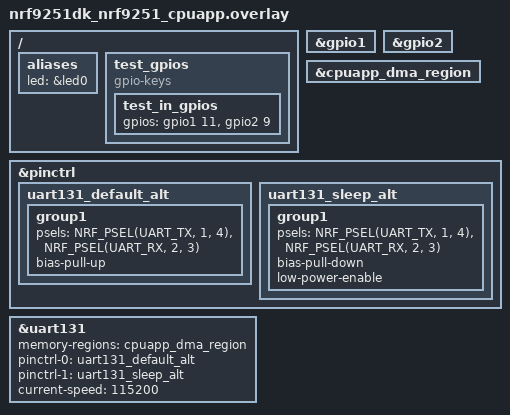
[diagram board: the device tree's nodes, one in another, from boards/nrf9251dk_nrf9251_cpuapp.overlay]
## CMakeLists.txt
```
#
# Copyright (c) 2026 Nordic Semiconductor ASA
#
# SPDX-License-Identifier: LicenseRef-Nordic-5-Clause
#

cmake_minimum_required(VERSION 3.20.0)

find_package(Zephyr REQUIRED HINTS $ENV{ZEPHYR_BASE})

project(uart_pins_pm)

target_sources(app PRIVATE src/main.c)
```

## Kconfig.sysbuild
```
#
# Copyright (c) 2026 Nordic Semiconductor ASA
#
# SPDX-License-Identifier: LicenseRef-Nordic-5-Clause
#

config REMOTE_BOARD
	string
	default "$(BOARD)/nrf54h20/cpurad" if SOC_NRF54H20_CPUAPP

source "share/sysbuild/Kconfig"
```

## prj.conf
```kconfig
CONFIG_SERIAL=y
CONFIG_UART_ASYNC_API=y

CONFIG_PM=y
CONFIG_PM_DEVICE=y
CONFIG_PM_DEVICE_RUNTIME=y
CONFIG_POWEROFF=y

CONFIG_BOOT_BANNER=n
CONFIG_NCS_BOOT_BANNER=n
CONFIG_ASSERT=y

# Enable for debugging purposes only
CONFIG_PRINTK=n
CONFIG_LOG=n
CONFIG_CONSOLE=n
CONFIG_UART_CONSOLE=n
```

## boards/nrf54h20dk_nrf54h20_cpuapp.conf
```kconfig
#
# Copyright (c) 2026 Nordic Semiconductor ASA
#
# SPDX-License-Identifier: LicenseRef-Nordic-5-Clause
#

CONFIG_SOC_NRF54H20_CPURAD_ENABLE=y
```

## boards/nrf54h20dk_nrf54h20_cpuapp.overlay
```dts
/*
 * Copyright (c) 2026 Nordic Semiconductor ASA
 *
 * SPDX-License-Identifier: LicenseRef-Nordic-5-Clause
 */

/*
 * Required loopbacks
 * P0.00 - P0.01
 * P0.02 - P0.04
 * P0.03 - P0.05
 * P0.06 - P0.07
 */

/ {
	aliases {
		led = &led0;
		/delete-property/ led1;
	};

	test_gpios {
		compatible = "gpio-keys";

		test_in_gpios: test_in_gpios {
			gpios = <&gpio0 1 GPIO_ACTIVE_HIGH>, <&gpio0 4 GPIO_ACTIVE_HIGH>,
				<&gpio0 5 GPIO_ACTIVE_HIGH>, <&gpio0 7 GPIO_ACTIVE_HIGH>;
		};
	};
};

/delete-node/ &led1;

&gpio0 {
	status = "okay";
};

&cpuapp_dma_region {
	status = "okay";
};

&pinctrl {
	uart132_default_alt: uart132_default_alt {
		group1 {
			psels = <NRF_PSEL(UART_TX, 0, 0)>,
				<NRF_PSEL(UART_RX, 0, 2)>,
				<NRF_PSEL(UART_RTS, 0, 3)>,
				<NRF_PSEL(UART_CTS, 0, 6)>;
			bias-pull-up;
		};
	};

	uart132_sleep_alt: uart132_sleep_alt {
		group1 {
			psels = <NRF_PSEL(UART_TX, 0, 0)>,
				<NRF_PSEL(UART_RX, 0, 2)>,
				<NRF_PSEL(UART_RTS, 0, 3)>,
				<NRF_PSEL(UART_CTS, 0, 6)>;
			bias-pull-down;
			low-power-enable;
		};
	};
};

dut: &uart132 {
	status = "okay";
	memory-regions = <&cpuapp_dma_region>;
	pinctrl-0 = <&uart132_default_alt>;
	pinctrl-1 = <&uart132_sleep_alt>;
	pinctrl-names = "default", "sleep";
	current-speed = <115200>;
	hw-flow-control;
	/delete-property/ zephyr,pm-device-runtime-auto;
};
```

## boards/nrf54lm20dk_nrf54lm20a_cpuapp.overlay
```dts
/*
 * Copyright (c) 2026 Nordic Semiconductor ASA
 *
 * SPDX-License-Identifier: LicenseRef-Nordic-5-Clause
 */

/*
 * Required loopbacks
 * P1.03 - P1.04
 * P1.13 - P1.14
 * P1.23 - P1.24
 * P1.30 - P1.31
 */

/ {
	aliases {
		led = &led0;
		/delete-property/ led1;
	};
};

/delete-node/ &led1;

/ {
	aliases {
		led = &led0;
		/delete-property/ led1;
	};

	test_gpios {
		compatible = "gpio-keys";

		test_in_gpios: test_in_gpios {
			gpios = <&gpio1 4 GPIO_ACTIVE_HIGH>, <&gpio1 14 GPIO_ACTIVE_HIGH>,
				<&gpio1 24 GPIO_ACTIVE_HIGH>, <&gpio1 31 GPIO_ACTIVE_HIGH>;
		};
	};
};

&gpio1 {
	status = "okay";
};

&pinctrl {
	uart21_default_alt: uart21_default_alt {
		group1 {
			psels = <NRF_PSEL(UART_TX, 1, 3)>,
				<NRF_PSEL(UART_RX, 1, 13)>,
				<NRF_PSEL(UART_RTS, 1, 23)>,
				<NRF_PSEL(UART_CTS, 1, 30)>;
			bias-pull-up;
		};
	};

	uart21_sleep_alt: uart21_sleep_alt {
		group1 {
			psels = <NRF_PSEL(UART_TX, 1, 3)>,
				<NRF_PSEL(UART_RX, 1, 13)>,
				<NRF_PSEL(UART_RTS, 1, 23)>,
				<NRF_PSEL(UART_CTS, 1, 30)>;
			bias-pull-down;
			low-power-enable;
		};
	};
};

dut: &uart21 {
	status = "okay";
	current-speed = <115200>;
	pinctrl-0 = <&uart21_default_alt>;
	pinctrl-1 = <&uart21_sleep_alt>;
	pinctrl-names = "default", "sleep";
	/delete-property/ zephyr,pm-device-runtime-auto;
};
```

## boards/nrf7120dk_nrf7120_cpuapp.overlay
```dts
/*
 * Copyright (c) 2026 Nordic Semiconductor ASA
 *
 * SPDX-License-Identifier: LicenseRef-Nordic-5-Clause
 */

/*
 * Required loopbacks
 * P1.07 - P1.12
 * P1.13 - P1.15
 * P1.14 - P1.05
 * P1.04 - P1.06
 */

/ {
	aliases {
		led = &led0;
		/delete-property/ led1;
	};
};

/delete-node/ &led1;

/ {
	aliases {
		led = &led0;
		/delete-property/ led1;
	};

	test_gpios {
		compatible = "gpio-keys";

		test_in_gpios: test_in_gpios {
			gpios = <&gpio1 7 GPIO_ACTIVE_HIGH>, <&gpio1 13 GPIO_ACTIVE_HIGH>,
				<&gpio1 14 GPIO_ACTIVE_HIGH>, <&gpio1 4 GPIO_ACTIVE_HIGH>;
		};
	};
};

&gpio1 {
	status = "okay";
};

&pinctrl {
	uart21_default_alt: uart21_default_alt {
		group1 {
			psels = <NRF_PSEL(UART_TX, 1, 12)>,
				<NRF_PSEL(UART_RX, 1, 15)>,
				<NRF_PSEL(UART_RTS, 1, 5)>,
				<NRF_PSEL(UART_CTS, 1, 6)>;
			bias-pull-up;
		};
	};

	uart21_sleep_alt: uart21_sleep_alt {
		group1 {
			psels = <NRF_PSEL(UART_TX, 1, 12)>,
				<NRF_PSEL(UART_RX, 1, 15)>,
				<NRF_PSEL(UART_RTS, 1, 5)>,
				<NRF_PSEL(UART_CTS, 1, 6)>;
			bias-pull-down;
			low-power-enable;
		};
	};
};

dut: &uart21 {
	status = "okay";
	current-speed = <115200>;
	pinctrl-0 = <&uart21_default_alt>;
	pinctrl-1 = <&uart21_sleep_alt>;
	pinctrl-names = "default", "sleep";
	/delete-property/ zephyr,pm-device-runtime-auto;
};

&gpio4 {
	status = "disabled";
};
```

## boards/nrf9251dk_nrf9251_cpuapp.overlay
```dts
/*
 * Copyright (c) 2026 Nordic Semiconductor ASA
 *
 * SPDX-License-Identifier: LicenseRef-Nordic-5-Clause
 */

/*
 * Required loopbacks
 * P1.04 - P1.11
 * P2.03 - P2.09
 */

/ {
	aliases {
		led = &led0;
	};

	test_gpios {
		compatible = "gpio-keys";

		test_in_gpios: test_in_gpios {
			gpios = <&gpio1 11 GPIO_ACTIVE_HIGH>, <&gpio2 9 GPIO_ACTIVE_HIGH>;
		};
	};
};

&gpio1 {
	status = "okay";
};

&gpio2 {
	status = "okay";
};

&cpuapp_dma_region {
	status = "okay";
};

&pinctrl {
	uart131_default_alt: uart131_default_alt {
		group1 {
			psels = <NRF_PSEL(UART_TX, 1, 4)>,
				<NRF_PSEL(UART_RX, 2, 3)>;
			bias-pull-up;
		};
	};

	uart131_sleep_alt: uart131_sleep_alt {
		group1 {
			psels = <NRF_PSEL(UART_TX, 1, 4)>,
				<NRF_PSEL(UART_RX, 2, 3)>;
			bias-pull-down;
			low-power-enable;
		};
	};
};

dut: &uart131 {
	status = "okay";
	memory-regions = <&cpuapp_dma_region>;
	pinctrl-0 = <&uart131_default_alt>;
	pinctrl-1 = <&uart131_sleep_alt>;
	pinctrl-names = "default", "sleep";
	current-speed = <115200>;
	/delete-property/ hw-flow-control;
	/delete-property/ zephyr,pm-device-runtime-auto;
};
```

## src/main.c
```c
/*
 * Copyright (c) 2026 Nordic Semiconductor ASA
 *
 * SPDX-License-Identifier: LicenseRef-Nordic-5-Clause
 */

#include <zephyr/drivers/uart.h>
#include <zephyr/pm/device_runtime.h>
#include <zephyr/pm/device.h>
#include <zephyr/kernel.h>
#include <zephyr/drivers/gpio.h>

static const struct device *const console_dev = DEVICE_DT_GET(DT_CHOSEN(zephyr_console));

#if DT_NODE_EXISTS(DT_NODELABEL(dut))
#define UART_NODE DT_NODELABEL(dut)
#else
#error Improper device tree configuration, UARTE test node not available
#endif

#define SLEEP_TIME_MS		    1000
#define UART_ACTION_BASE_TIMEOUT_US 1000
#define TEST_BUFFER_LEN		    10

static uint8_t test_buffer[TEST_BUFFER_LEN];
const uint8_t test_pattern[TEST_BUFFER_LEN] = {0x11, 0x12, 0x13, 0x14, 0x15,
					       0x16, 0x17, 0x18, 0x19, 0x20};

static const struct device *const uart_dev = DEVICE_DT_GET(UART_NODE);
static const struct gpio_dt_spec led = GPIO_DT_SPEC_GET(DT_ALIAS(led), gpios);

const struct gpio_dt_spec test_pins[] = {DT_FOREACH_PROP_ELEM_SEP(
	DT_NODELABEL(test_in_gpios), gpios, GPIO_DT_SPEC_GET_BY_IDX, (,))};

static void async_uart_callback(const struct device *dev, struct uart_event *evt, void *user_data)
{
	switch (evt->type) {
	case UART_TX_DONE:
		printk("UART_TX_DONE\n");
		break;
	case UART_TX_ABORTED:
		printk("UART_TX_ABORTED\n");
		break;
	case UART_RX_RDY:
		printk("UART_RX_RDY\n");
		break;
	case UART_RX_BUF_RELEASED:
		printk("UART_RX_BUF_RELEASED\n");
		break;
	case UART_RX_BUF_REQUEST:
		printk("UART_RX_BUF_REQUEST\n");
		break;
	case UART_RX_DISABLED:
		printk("UART_RX_DISABLED\n");
		break;
	default:
		break;
	}
}

void enable_uart_rx(void)
{
	int err;

	err = uart_rx_enable(uart_dev, test_buffer, TEST_BUFFER_LEN,
			     5 * UART_ACTION_BASE_TIMEOUT_US);
	if (err != 0) {
		printk("Unexpected error when enabling UART RX: %d\n", err);
	}
}

void disable_uart_rx(void)
{
	k_busy_wait(5000);
	uart_rx_disable(uart_dev);
	k_busy_wait(5000);
}

void configure_test_pins(void)
{
	int err;

	for (int i = 0; i < ARRAY_SIZE(test_pins); i++) {
		__ASSERT(gpio_is_ready_dt(&test_pins[i]) == 1, "Test pin %u is not ready\n", i);
		err = gpio_pin_configure_dt(&test_pins[i], GPIO_INPUT);
		__ASSERT(err == 0, "Test pin %u configuration failed\n: %d", i, err);
	}
}

int main(void)
{
	int err;
	uint8_t pin_state;

	printk("UART instance: %s\n", uart_dev->name);

	err = gpio_is_ready_dt(&led);
	__ASSERT(err == 1, "Error: LED gpio is not ready");

	err = gpio_pin_configure_dt(&led, GPIO_OUTPUT_ACTIVE);
	__ASSERT(err == 0, "Could not configure led GPIO");

	err = uart_callback_set(uart_dev, async_uart_callback, NULL);
	__ASSERT(err == 0, "UART callback set failed: %d\n", err);

	pm_device_runtime_enable(console_dev);

	configure_test_pins();
	gpio_pin_set_dt(&led, 0);

	while (1) {
		enable_uart_rx();
		uart_tx(uart_dev, test_pattern, TEST_BUFFER_LEN, UART_ACTION_BASE_TIMEOUT_US);
		disable_uart_rx();

		pm_device_runtime_put(uart_dev);

		/* Suspending UART device must release its pins */
		for (int i = 0; i < ARRAY_SIZE(test_pins); i++) {
			k_busy_wait(1000);
			pin_state = gpio_pin_get_dt(&test_pins[i]);
			printk("Pin %u, state: %u\n", i, pin_state);
			__ASSERT(pin_state == 0, "Test pin %u is in HIGH state\n", i);
		}

		gpio_pin_set_dt(&led, 0);
		k_msleep(SLEEP_TIME_MS);
		gpio_pin_set_dt(&led, 1);
		pm_device_runtime_get(uart_dev);
	}

	return 0;
}
```
